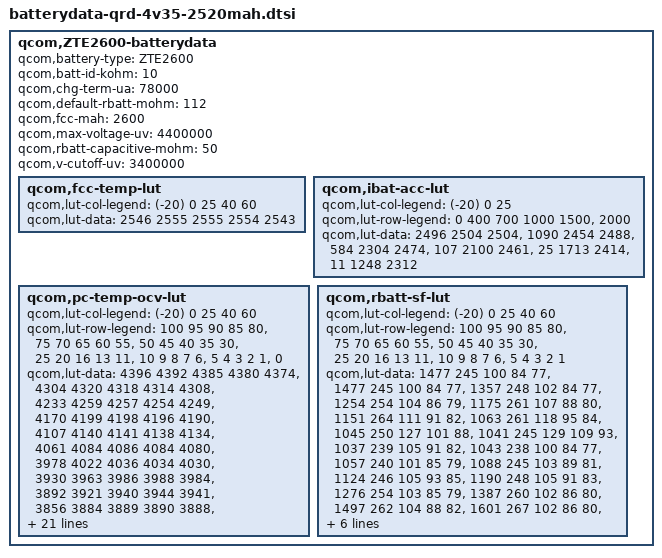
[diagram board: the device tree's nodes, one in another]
/* Copyright (c) 2013, The Linux Foundation. All rights reserved.
 *
 * This program is free software; you can redistribute it and/or modify
 * it under the terms of the GNU General Public License version 2 and
 * only version 2 as published by the Free Software Foundation.
 *
 * This program is distributed in the hope that it will be useful,
 * but WITHOUT ANY WARRANTY; without even the implied warranty of
 * MERCHANTABILITY or FITNESS FOR A PARTICULAR PURPOSE.  See the
 * GNU General Public License for more details.
 */

qcom,ZTE2600-batterydata {
	qcom,battery-type = "ZTE2600";
	qcom,batt-id-kohm = <10>;
	qcom,chg-term-ua = <78000>;
	qcom,default-rbatt-mohm = <112>;
	qcom,fcc-mah = <2600>;
	qcom,max-voltage-uv = <4400000>;
	qcom,rbatt-capacitive-mohm = <50>;
	qcom,v-cutoff-uv = <3400000>;

	qcom,fcc-temp-lut {
		qcom,lut-col-legend = <(-20) 0 25 40 60>;
		qcom,lut-data = <2546 2555 2555 2554 2543>;
	};

	qcom,ibat-acc-lut {
		qcom,lut-col-legend = <(-20) 0 25>;
		qcom,lut-row-legend = <0 400 700 1000 1500>,
					<2000>;
		qcom,lut-data = <2496 2504 2504>,
				<1090 2454 2488>,
				<584 2304 2474>,
				<107 2100 2461>,
				<25 1713 2414>,
				<11 1248 2312>;
	};

	qcom,pc-temp-ocv-lut {
		qcom,lut-col-legend = <(-20) 0 25 40 60>;
		qcom,lut-row-legend = <100 95 90 85 80>,
					<75 70 65 60 55>,
					<50 45 40 35 30>,
					<25 20 16 13 11>,
					<10 9 8 7 6>,
					<5 4 3 2 1>,
					<0>;
		qcom,lut-data = <4396 4392 4385 4380 4374>,
				<4304 4320 4318 4314 4308>,
				<4233 4259 4257 4254 4249>,
				<4170 4199 4198 4196 4190>,
				<4107 4140 4141 4138 4134>,
				<4061 4084 4086 4084 4080>,
				<3978 4022 4036 4034 4030>,
				<3930 3963 3986 3988 3984>,
				<3892 3921 3940 3944 3941>,
				<3856 3884 3889 3890 3888>,
				<3826 3852 3854 3853 3852>,
				<3803 3825 3828 3827 3826>,
				<3786 3803 3806 3806 3804>,
				<3772 3784 3789 3789 3786>,
				<3760 3770 3773 3771 3764>,
				<3744 3758 3756 3749 3738>,
				<3728 3741 3738 3728 3715>,
				<3712 3724 3717 3708 3695>,
				<3696 3710 3699 3690 3678>,
				<3682 3702 3688 3680 3668>,
				<3674 3699 3687 3678 3667>,
				<3664 3695 3685 3677 3666>,
				<3654 3691 3683 3675 3664>,
				<3640 3686 3680 3672 3659>,
				<3624 3676 3670 3662 3646>,
				<3602 3654 3646 3634 3614>,
				<3569 3612 3600 3587 3567>,
				<3522 3551 3537 3525 3508>,
				<3446 3461 3452 3440 3426>,
				<3304 3318 3318 3308 3299>,
				<3000 3000 3000 3028 3008>;
	};

	qcom,rbatt-sf-lut {
		qcom,lut-col-legend = <(-20) 0 25 40 60>;
		qcom,lut-row-legend = <100 95 90 85 80>,
					<75 70 65 60 55>,
					<50 45 40 35 30>,
					<25 20 16 13 11>,
					<10 9 8 7 6>,
					<5 4 3 2 1>;
		qcom,lut-data = <1477 245 100 84 77>,
				<1477 245 100 84 77>,
				<1357 248 102 84 77>,
				<1254 254 104 86 79>,
				<1175 261 107 88 80>,
				<1151 264 111 91 82>,
				<1063 261 118 95 84>,
				<1045 250 127 101 88>,
				<1041 245 129 109 93>,
				<1037 239 105 91 82>,
				<1043 238 100 84 77>,
				<1057 240 101 85 79>,
				<1088 245 103 89 81>,
				<1124 246 105 93 85>,
				<1190 248 105 91 83>,
				<1276 254 103 85 79>,
				<1387 260 102 86 80>,
				<1497 262 104 88 82>,
				<1601 267 102 86 80>,
				<1682 277 102 84 79>,
				<1727 284 104 87 81>,
				<1757 288 105 89 84>,
				<1723 293 107 92 88>,
				<1825 304 112 97 91>,
				<1967 318 114 98 90>,
				<2252 325 112 92 85>,
				<2777 331 110 92 86>,
				<3713 364 114 95 89>,
				<5747 448 126 106 98>,
				<11495 896 252 212 132>;
	};
};

